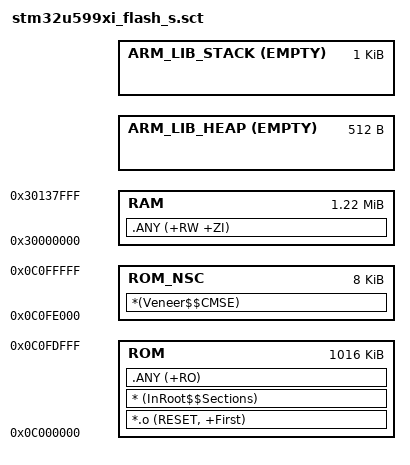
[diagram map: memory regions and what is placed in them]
#! armclang -E --target=arm-arm-none-eabi -xc
; command above MUST be in first line (no comment above!)

; ******************************************************************************
; * @file    stm32u599xi_flash_s.sct
; * @brief   Linker File
; ******************************************************************************
; * @attention
; *
; * Copyright (c) 2022-2025 STMicroelectronics.
; * All rights reserved.
; *
; * This software is licensed under terms that can be found in the LICENSE file
; * in the root directory of this software component.
; * If no LICENSE file comes with this software, it is provided AS-IS.
; *
; ******************************************************************************

#define __HEAP_SIZE 0x200
#define __STACK_SIZE 0x400


ROM 0xC000000 0xFE000
{
  ROM 0xC000000 0xFE000
  {
    *.o (RESET, +First)
    * (InRoot$$Sections)
    .ANY (+RO)
  }

  RAM 0x30000000 0x138000
  {
    .ANY (+RW +ZI)
  }

  ARM_LIB_HEAP AlignExpr(+0, 8) EMPTY  __HEAP_SIZE
  {
  }

  ARM_LIB_STACK AlignExpr(+0, 8) EMPTY  __STACK_SIZE
  {
  }
}

ROM_NSC 0xC0FE000 0x2000
{
  ROM_NSC 0xC0FE000 0x2000
  {
    *(Veneer$$CMSE)
  }
}
